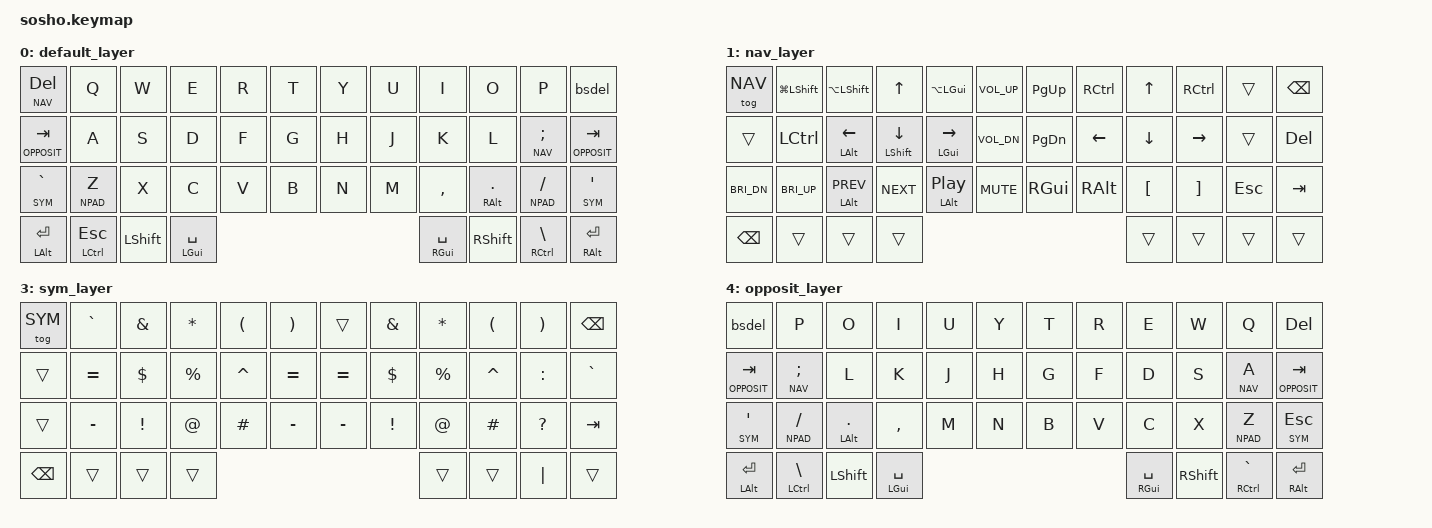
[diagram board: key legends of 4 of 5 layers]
/*
 * spinko-sosho keymap for the Elekit SO-SHO TH-601 (44-key split with L-trackpad, R-trackball).
 * Translated from justindwyer6/qmk_firmware keyboards/lets_split/keymaps/spinko/keymap.c.
 */

#define ZMK_POINTING_DEFAULT_SCRL_VAL 500

#include <behaviors.dtsi>
#include <input/processors.dtsi>
#include <zephyr/dt-bindings/input/input-event-codes.h>
#include <dt-bindings/zmk/bt.h>
#include <dt-bindings/zmk/keys.h>
#include <dt-bindings/zmk/pointing.h>
#include <dt-bindings/zmk/outputs.h>

#define QWERTY  0
#define NAV     1
#define NPAD    2
#define SYM     3
#define OPPOSIT 4

/ {
    behaviors {
// Shift+Backspace -> Delete. Cmd/Ctrl/Alt+Backspace stays as real
        // Backspace so Cmd+Bspc still deletes lines / Opt+Bspc still deletes
        // words on macOS.
        bsdel: bsdel {
            compatible = "zmk,behavior-mod-morph";
            #binding-cells = <0>;
            bindings = <&kp BSPC>, <&kp DEL>;
            mods = <(MOD_LSFT|MOD_RSFT)>;
        };

        // Thumb-row mod-tap. Strict tap-preferred so fast typing on the space
        // and other thumb dual-purpose keys never accidentally engages the
        // modifier. Tapping-term is longer than default because thumbs move
        // more slowly than fingers; require-prior-idle-ms suppresses the hold
        // if a normal key was just pressed (i.e., during a typing flow).
        thmt: thumb_modtap {
            compatible = "zmk,behavior-hold-tap";
            #binding-cells = <2>;
            tapping-term-ms = <250>;
            quick-tap-ms = <175>;
            require-prior-idle-ms = <150>;
            flavor = "tap-preferred";
            bindings = <&kp>, <&kp>;
        };

        // Encoder mouse-scroll behavior. Default layer: both encoders scroll
        // vertically. NAV layer: both scroll horizontally.
        ec_ms_l: ec_ms_h {
            compatible = "zmk,behavior-encoder-mouse-scroll";
            #sensor-binding-cells = <2>;
        };
        ec_ms_r: ec_ms_v {
            compatible = "zmk,behavior-encoder-mouse-scroll";
            #sensor-binding-cells = <2>;
        };
    };
};

&msc {
    time-to-max-speed-ms = <0>;
    acceleration-exponent = <0>;
};

/ {
    // Scaler applied to wheel/hwheel events (not raw XY). track-remainders
    // preserves fractional motion between events so slow trackball movement
    // still accumulates into a scroll tick instead of getting truncated.
    zip_scroll_scaler: zip_scroll_scaler {
        compatible = "zmk,input-processor-scaler";
        #input-processor-cells = <2>;
        type = <INPUT_EV_REL>;
        codes = <INPUT_REL_WHEEL INPUT_REL_HWHEEL>;
        track-remainders;
    };
};

/ {
    // Right-hand home-row combos for mouse clicks (matches upstream Elekit defaults).
    //   J + K -> LCLK   (positions 19, 20)
    //   K + L -> RCLK   (positions 20, 21)
    //   J + L -> MCLK   (positions 19, 21) -- slightly longer window
    combos {
        compatible = "zmk,combos";
        combo_LCLK {
            timeout-ms = <50>;
            key-positions = <19 20>;
            bindings = <&mkp LCLK>;
        };
        combo_RCLK {
            timeout-ms = <50>;
            key-positions = <20 21>;
            bindings = <&mkp RCLK>;
        };
        combo_MCLK {
            timeout-ms = <90>;
            key-positions = <19 21>;
            bindings = <&mkp MCLK>;
        };
    };

    keymap {
        compatible = "zmk,keymap";

        default_layer {
            // Base QWERTY. Mouse clicks come from J/K/L combos (see combos block above).
            // Thumb row (row 3): outer=ENTER, inner-outer=Ctrl/Esc, then Shift,
            // then innermost=Cmd/Space -- matches the original spinko layout.
            bindings = <
&lt NAV DEL     &kp Q       &kp W  &kp E              &kp R              &kp T          &kp Y  &kp U              &kp I              &kp O         &kp P          &bsdel
&lt OPPOSIT TAB &kp A       &kp S  &kp D              &kp F              &kp G          &kp H  &kp J              &kp K              &kp L         &lt NAV SEMI   &lt OPPOSIT TAB
&lt SYM GRAVE   &lt NPAD Z  &kp X  &kp C              &kp V              &kp B          &kp N  &kp M              &kp COMMA          &thmt RALT DOT  &lt NPAD FSLH  &lt SYM SQT
&thmt LALT ENTER  &thmt LCTRL ESC                         &kp LSHFT          &thmt LGUI SPACE     &thmt RGUI SPACE         &kp RSHFT          &thmt RCTRL BSLH &thmt RALT ENTER
            >;

            // Both encoders scroll vertically. Hold NAV for horizontal scroll.
            // Brightness/volume are still reachable via keys on the NAV layer.
            sensor-bindings = <&ec_ms_l SCRL_DOWN SCRL_UP  &ec_ms_r SCRL_DOWN SCRL_UP>;
        };

        nav_layer {
            // spinko _NAV: arrows on right home row, media/brightness/volume on left, page-nav on inner columns.
            // Also the "scroll mode" for the right trackball -- see trackball_listener at the
            // bottom of this file. Hold &lt NAV DEL (top-left of default) to scroll with the
            // ball momentarily; release to return to cursor. Encoders are horizontal (L) /
            // vertical (R) scroll while NAV is active.
            bindings = <
&tog NAV      &kp LG(LSHFT)   &kp LA(LSHFT)    &kp UP           &kp LA(LGUI)     &kp C_VOL_UP    &kp PG_UP  &kp RCTRL  &kp UP        &kp RCTRL  &trans   &kp BSPC
&trans        &kp LCTRL       &mt LALT LEFT    &mt LSHFT DOWN   &mt LGUI RIGHT   &kp C_VOL_DN    &kp PG_DN  &kp LEFT   &kp DOWN      &kp RIGHT  &trans   &kp DEL
&kp C_BRI_DN  &kp C_BRI_UP    &mt LALT C_PREV  &kp C_NEXT       &mt LALT C_PP    &kp C_MUTE      &kp RGUI   &kp RALT   &kp LBKT      &kp RBKT   &kp ESC  &kp TAB
&kp BSPC      &trans                                            &trans           &trans          &trans     &trans                                &trans   &trans
            >;

            // Both encoders scroll horizontally on NAV (trackball still vertical).
            sensor-bindings = <&ec_ms_l SCRL_LEFT SCRL_RIGHT  &ec_ms_r SCRL_LEFT SCRL_RIGHT>;
        };

        npad_layer {
            // spinko _NPAD.
            bindings = <
&tog NPAD  &trans  &kp N7  &kp N8  &kp N9  &kp BSPC    &trans  &kp N7  &kp N8  &kp N9  &kp N0  &kp BSPC
&trans     &trans  &kp N4  &kp N5  &kp N6  &kp DOT     &trans  &kp N4  &kp N5  &kp N6  &trans  &kp DEL
&trans     &trans  &kp N1  &kp N2  &kp N3  &kp N0      &kp N0  &kp N1  &kp N2  &kp N3  &trans  &kp TAB
&kp BSPC   &trans                          &trans      &trans  &trans                          &trans  &trans
            >;
        };

        sym_layer {
            // spinko _SYM with math keys added on the inner columns:
            //   G / H -> =   (both hands = equal)
            //   B / N -> -   (both hands = minus)
            bindings = <
&tog SYM  &kp GRAVE  &kp AMPS   &kp STAR   &kp LPAR   &kp RPAR    &trans      &kp AMPS  &kp STAR   &kp LPAR   &kp RPAR   &kp BSPC
&trans    &kp EQUAL  &kp DLLR   &kp PRCNT  &kp CARET  &kp EQUAL   &kp EQUAL   &kp DLLR  &kp PRCNT  &kp CARET  &kp COLON  &kp GRAVE
&trans    &kp MINUS  &kp EXCL   &kp AT     &kp HASH   &kp MINUS   &kp MINUS   &kp EXCL  &kp AT     &kp HASH   &kp QMARK  &kp TAB
&kp BSPC  &trans                          &trans      &trans      &trans  &trans                                         &kp PIPE   &trans
            >;
        };

        opposit_layer {
            // Horizontal mirror of QWERTY for one-handed typing.
            // Hold either TAB (row 1 pos 12 or 23) to enter momentarily.
            // Letters mirror strictly; mod-tap prefixes follow physical side.
            // Ergonomic tunings vs. strict mirror:
            //   - pos 11 = plain DEL (no NAV-hold on top-row DEL)
            //   - pos 22 = &lt NAV A (NAV pinky-hold added for one-hand access)
            //   - pos 35 = &lt SYM ESC (spinko's GRV->ESC swap on this pinky)
            //   - pos 42 = &thmt RCTRL GRAVE (spinko's ESC->GRV swap on this thumb)
            bindings = <
&bsdel           &kp P              &kp O            &kp I              &kp U              &kp Y          &kp T  &kp R              &kp E              &kp W          &kp Q          &kp DEL
&lt OPPOSIT TAB  &lt NAV SEMI       &kp L            &kp K              &kp J              &kp H          &kp G  &kp F              &kp D              &kp S          &lt NAV A      &lt OPPOSIT TAB
&lt SYM SQT      &lt NPAD FSLH      &thmt LALT DOT     &kp COMMA          &kp M              &kp N          &kp B  &kp V              &kp C              &kp X          &lt NPAD Z     &lt SYM ESC
&thmt LALT ENTER   &thmt LCTRL BSLH                                         &kp LSHFT          &thmt LGUI SPACE     &thmt RGUI SPACE         &kp RSHFT          &thmt RCTRL GRAVE &thmt RALT ENTER
            >;
        };
    };
};

// Turn the trackball (right, on-central) into a scroll wheel while the
// NAV layer is active. Hold &lt NAV DEL (top-left of default) -> scroll;
// release -> cursor. Encoders also switch to horizontal/vertical scroll
// on NAV (see nav_layer sensor-bindings above).
// Scaling is applied AFTER the XY->scroll mapping via zip_scroll_scaler,
// which uses track-remainders so slow motion accumulates instead of being
// truncated to zero. 1/8 is a moderate divisor -- lower it for slower scroll.
&trackball_listener {
    scroll_on_nav {
        layers = <NAV>;
        input-processors = <&zip_xy_to_scroll_mapper>, <&zip_scroll_scaler 1 8>;
    };
};

// Trackpad (left, forwarded via split) reverts to stock behavior:
// cursor motion + tap-to-click. No processor overrides.
